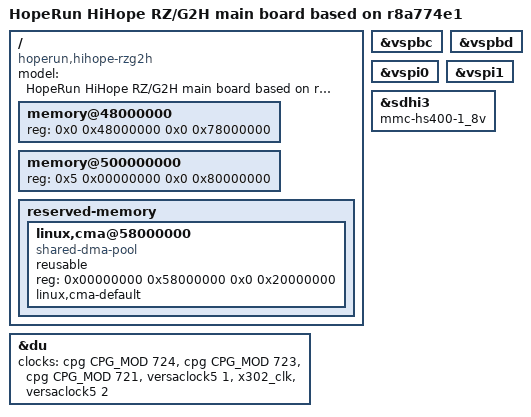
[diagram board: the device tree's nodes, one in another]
// SPDX-License-Identifier: GPL-2.0
/*
 * Device Tree Source for the HiHope RZ/G2H main board
 *
 * Copyright (C) 2020 Renesas Electronics Corp.
 */

/dts-v1/;
#include "r8a774e1.dtsi"
#include "hihope-rev4.dtsi"

/ {
	model = "HopeRun HiHope RZ/G2H main board based on r8a774e1";
	compatible = "hoperun,hihope-rzg2h", "renesas,r8a774e1";

	memory@48000000 {
		device_type = "memory";
		/* first 128MB is reserved for secure area. */
		reg = <0x0 0x48000000 0x0 0x78000000>;
	};

	memory@500000000 {
		device_type = "memory";
		reg = <0x5 0x00000000 0x0 0x80000000>;
	};

	reserved-memory {
		#address-cells = <2>;
		#size-cells = <2>;
		ranges;

		/* global autoconfigured region for contiguous allocations */
		linux,cma@58000000 {
			compatible = "shared-dma-pool";
			reusable;
			reg = <0x00000000 0x58000000 0x0 0x20000000>;
			linux,cma-default;
		};
	};
};

&du {
	clocks = <&cpg CPG_MOD 724>,
		 <&cpg CPG_MOD 723>,
		 <&cpg CPG_MOD 721>,
		 <&versaclock5 1>,
		 <&x302_clk>,
		 <&versaclock5 2>;
	clock-names = "du.0", "du.1", "du.3",
		      "dclkin.0", "dclkin.1", "dclkin.3";
};

&vspbc {
	status = "okay";
};

&vspbd {
	status = "okay";
};

&vspi0 {
	status = "okay";
};

&vspi1 {
	status = "okay";
};

&sdhi3 {
	mmc-hs400-1_8v;
};
